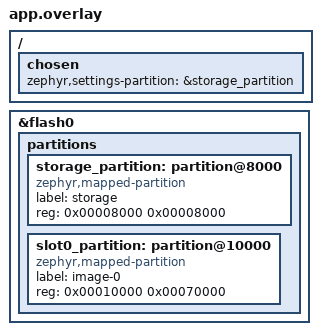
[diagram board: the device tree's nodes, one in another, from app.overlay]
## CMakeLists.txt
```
# Copyright (c) 2026 favoritewky
# SPDX-License-Identifier: Apache-2.0

cmake_minimum_required(VERSION 3.20.0)

find_package(Zephyr REQUIRED HINTS $ENV{ZEPHYR_BASE})

project(romstart_flash_base)

FILE(GLOB app_sources src/*.c)
target_sources(app PRIVATE ${app_sources})
```

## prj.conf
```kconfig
CONFIG_ZTEST=y

# Link the application image into the code partition and keep the boot
# vectors at the base of zephyr,flash
CONFIG_USE_DT_CODE_PARTITION=y
CONFIG_ROMSTART_RELOCATION_ROM=y
CONFIG_ROMSTART_REGION_AT_FLASH_BASE=y

# Exercise a settings backend on the storage partition placed between
# the vector table and the application image
CONFIG_FLASH=y
CONFIG_FLASH_MAP=y
CONFIG_SETTINGS=y
CONFIG_NVS=y
CONFIG_SETTINGS_NVS=y
```

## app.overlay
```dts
/*
 * Copyright (c) 2026 favoritewky
 * SPDX-License-Identifier: Apache-2.0
 */

/* Move the code partition above a storage partition that sits in the
 * first flash sectors, right after the boot vectors at the base of
 * flash. STM32F401RE: sectors 0/1 are 16KB each (boot vectors), sectors
 * 2/3 are 16KB each (storage), sectors 4-11 host the 64KB-aligned
 * application image.
 */

&flash0 {
	#address-cells = <1>;
	#size-cells = <1>;
	ranges = <0x0 0x08000000 0x80000>;

	partitions {
		ranges;

		/delete-node/ partition@0;
		/delete-node/ partition@20000;
		/delete-node/ partition@40000;
		/delete-node/ partition@60000;

		storage_partition: partition@8000 {
			compatible = "zephyr,mapped-partition";
			label = "storage";
			reg = <0x00008000 0x00008000>;
		};

		slot0_partition: partition@10000 {
			compatible = "zephyr,mapped-partition";
			label = "image-0";
			reg = <0x00010000 0x00070000>;
		};
	};
};

/ {
	chosen {
		zephyr,settings-partition = &storage_partition;
	};
};
```

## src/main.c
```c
/*
 * Copyright (c) 2026 favoritewky
 *
 * SPDX-License-Identifier: Apache-2.0
 */

#include <zephyr/kernel.h>
#include <zephyr/ztest.h>
#include <zephyr/devicetree.h>
#include <zephyr/settings/settings.h>
#include <cmsis_core.h>

extern char __rom_region_start[];

#define STORAGE_NODE   DT_CHOSEN(zephyr_settings_partition)
#define CODE_NODE      DT_CHOSEN(zephyr_code_partition)

/* The storage partition is expected to sit in the flash between the
 * boot vectors at the base of flash and the application image.
 */
#define STORAGE_ADDR DT_REG_ADDR(STORAGE_NODE)
#define STORAGE_SIZE DT_REG_SIZE(STORAGE_NODE)

ZTEST(romstart_flash_base, test_vector_table_at_flash_base)
{
	/* The vector table must stay at the address the SoC boots from,
	 * which is the base of the flash region, not the start of the
	 * application image in the code partition.
	 */
	zassert_equal(SCB->VTOR, CONFIG_ROMSTART_REGION_ADDRESS,
		      "vector table at 0x%08x, expected 0x%08x",
		      (unsigned int)SCB->VTOR, (unsigned int)FLASH_BASE);
}

ZTEST(romstart_flash_base, test_image_in_code_partition)
{
	/* The application image must be linked at the code partition,
	 * leaving the flash below it untouched.
	 */
	zassert_equal((uintptr_t)__rom_region_start,
		      DT_REG_ADDR(CODE_NODE),
		      "image at 0x%08x, code partition at 0x%08x",
		      (unsigned int)(uintptr_t)__rom_region_start,
		      (unsigned int)DT_REG_ADDR(CODE_NODE));

	/* The storage partition must be fully below the image, so that
	 * flashing the image does not erase it.
	 */
	zassert_true(STORAGE_ADDR + STORAGE_SIZE <= (uintptr_t)__rom_region_start,
		     "storage [0x%08x, 0x%08x) overlaps image at 0x%08x",
		     (unsigned int)STORAGE_ADDR,
		     (unsigned int)(STORAGE_ADDR + STORAGE_SIZE),
		     (unsigned int)(uintptr_t)__rom_region_start);
}

static uint8_t expected_value;
static uint8_t loaded_value;
static bool value_loaded;

static int romstart_settings_set(const char *key, size_t len,
				 settings_read_cb read_cb, void *cb_arg)
{
	if (strcmp(key, "test") != 0) {
		return -ENOENT;
	}
	if (len != sizeof(loaded_value)) {
		return -EINVAL;
	}
	read_cb(cb_arg, &loaded_value, sizeof(loaded_value));
	value_loaded = true;

	return 0;
}

SETTINGS_STATIC_HANDLER_DEFINE(romstart, "romstart", NULL,
			       romstart_settings_set, NULL, NULL);

ZTEST(romstart_flash_base, test_settings_survives_partition)
{
	int ret;

	ret = settings_subsys_init();
	zassert_ok(ret, "settings init failed");

	expected_value = 0xa5;
	ret = settings_save_one("romstart/test", &expected_value,
				sizeof(expected_value));
	zassert_ok(ret, "settings save failed");

	loaded_value = 0;
	value_loaded = false;
	ret = settings_load();
	zassert_ok(ret, "settings load failed");
	zassert_true(value_loaded, "settings entry not loaded back");
	zassert_equal(loaded_value, expected_value, "value mismatch");
}

ZTEST_SUITE(romstart_flash_base, NULL, NULL, NULL, NULL, NULL);
```
